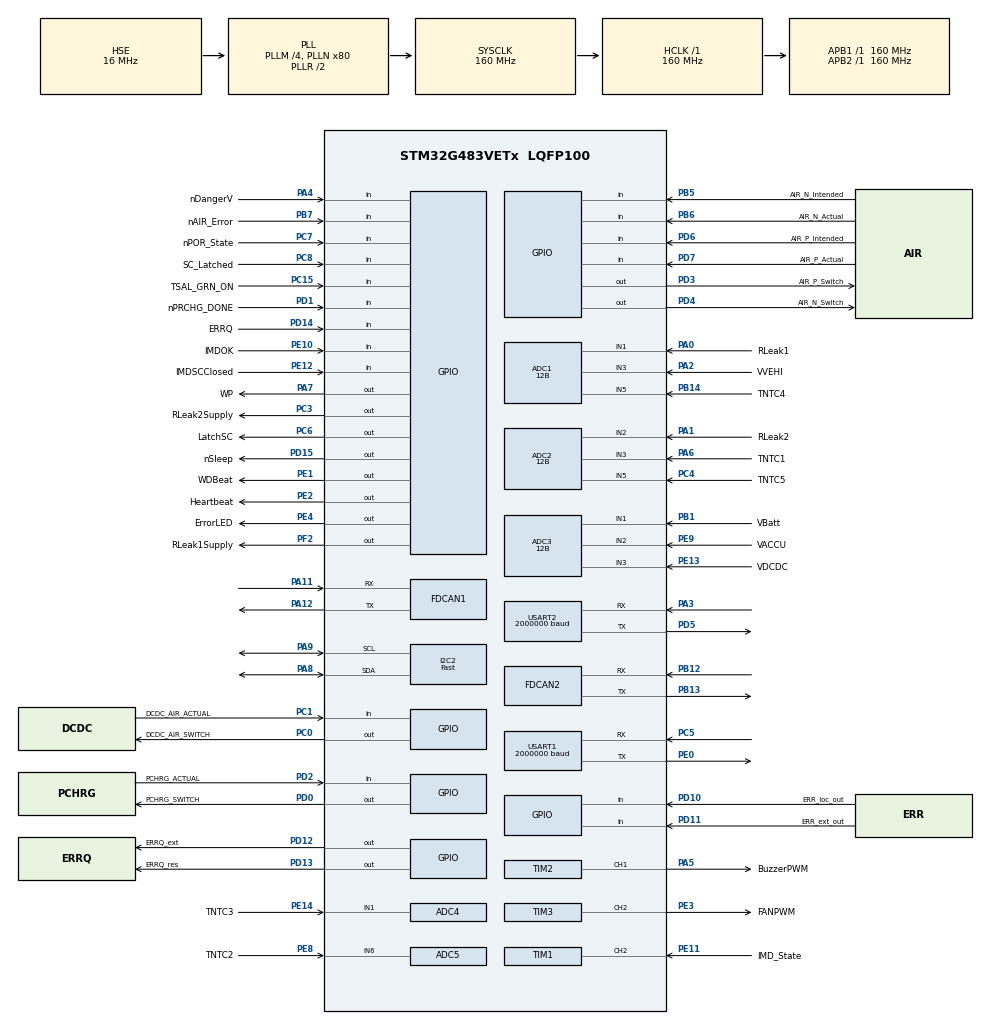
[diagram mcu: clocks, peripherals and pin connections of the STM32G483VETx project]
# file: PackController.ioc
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ADC1.Channel-0\#ChannelRegularConversion=ADC_CHANNEL_1
ADC1.Channel-1\#ChannelRegularConversion=ADC_CHANNEL_3
ADC1.Channel-2\#ChannelRegularConversion=ADC_CHANNEL_5
ADC1.Channel-3\#ChannelRegularConversion=ADC_CHANNEL_VREFINT
ADC1.Channel-IN=ADC_CHANNEL_VREFINT
ADC1.ClockPrescaler=ADC_CLOCK_SYNC_PCLK_DIV4
ADC1.ContinuousConvMode=DISABLE
ADC1.DMAContinuousRequests=ENABLE
ADC1.EOCSelection=ADC_EOC_SEQ_CONV
ADC1.ExternalTrigConv=ADC_EXTERNALTRIG_T6_TRGO
ADC1.ExternalTrigConvEdge=ADC_EXTERNALTRIGCONVEDGE_RISING
ADC1.NbrOfConversion=4
ADC1.NbrOfConversionFlag=1
ADC1.OffsetNumber-0\#ChannelRegularConversion=ADC_OFFSET_NONE
ADC1.OffsetNumber-1\#ChannelRegularConversion=ADC_OFFSET_NONE
ADC1.OffsetNumber-2\#ChannelRegularConversion=ADC_OFFSET_NONE
ADC1.OffsetNumber-3\#ChannelRegularConversion=ADC_OFFSET_NONE
ADC1.Overrun=ADC_OVR_DATA_OVERWRITTEN
ADC1.Rank-0\#ChannelRegularConversion=1
ADC1.Rank-1\#ChannelRegularConversion=2
ADC1.Rank-2\#ChannelRegularConversion=3
ADC1.Rank-3\#ChannelRegularConversion=4
ADC1.Resolution=ADC_RESOLUTION_12B
ADC1.SamplingTime-0\#ChannelRegularConversion=ADC_SAMPLETIME_247CYCLES_5
ADC1.SamplingTime-1\#ChannelRegularConversion=ADC_SAMPLETIME_92CYCLES_5
ADC1.SamplingTime-2\#ChannelRegularConversion=ADC_SAMPLETIME_92CYCLES_5
ADC1.SamplingTime-3\#ChannelRegularConversion=ADC_SAMPLETIME_247CYCLES_5
ADC1.ScanConvMode=ADC_SCAN_ENABLE
ADC1.master=1
ADC2.Channel-0\#ChannelRegularConversion=ADC_CHANNEL_2
ADC2.Channel-1\#ChannelRegularConversion=ADC_CHANNEL_3
ADC2.Channel-2\#ChannelRegularConversion=ADC_CHANNEL_5
ADC2.ClockPrescaler=ADC_CLOCK_SYNC_PCLK_DIV4
ADC2.ContinuousConvMode=DISABLE
ADC2.DMAContinuousRequests=ENABLE
ADC2.EOCSelection=ADC_EOC_SEQ_CONV
ADC2.ExternalTrigConv=ADC_EXTERNALTRIG_T6_TRGO
ADC2.ExternalTrigConvEdge=ADC_EXTERNALTRIGCONVEDGE_RISING
ADC2.NbrOfConversion=3
ADC2.NbrOfConversionFlag=1
ADC2.OffsetNumber-0\#ChannelRegularConversion=ADC_OFFSET_NONE
ADC2.OffsetNumber-1\#ChannelRegularConversion=ADC_OFFSET_NONE
ADC2.OffsetNumber-2\#ChannelRegularConversion=ADC_OFFSET_NONE
ADC2.Overrun=ADC_OVR_DATA_OVERWRITTEN
ADC2.Rank-0\#ChannelRegularConversion=1
ADC2.Rank-1\#ChannelRegularConversion=2
ADC2.Rank-2\#ChannelRegularConversion=3
ADC2.Resolution=ADC_RESOLUTION_12B
ADC2.SamplingTime-0\#ChannelRegularConversion=ADC_SAMPLETIME_247CYCLES_5
ADC2.SamplingTime-1\#ChannelRegularConversion=ADC_SAMPLETIME_92CYCLES_5
ADC2.SamplingTime-2\#ChannelRegularConversion=ADC_SAMPLETIME_92CYCLES_5
ADC2.ScanConvMode=ADC_SCAN_ENABLE
ADC3.Channel-0\#ChannelRegularConversion=ADC_CHANNEL_1
ADC3.Channel-1\#ChannelRegularConversion=ADC_CHANNEL_2
ADC3.Channel-2\#ChannelRegularConversion=ADC_CHANNEL_3
ADC3.ClockPrescaler=ADC_CLOCK_SYNC_PCLK_DIV4
ADC3.ContinuousConvMode=DISABLE
ADC3.DMAContinuousRequests=ENABLE
ADC3.EOCSelection=ADC_EOC_SEQ_CONV
ADC3.ExternalTrigConv=ADC_EXTERNALTRIG_T6_TRGO
ADC3.ExternalTrigConvEdge=ADC_EXTERNALTRIGCONVEDGE_RISING
ADC3.NbrOfConversion=3
ADC3.NbrOfConversionFlag=1
ADC3.OffsetNumber-0\#ChannelRegularConversion=ADC_OFFSET_NONE
ADC3.OffsetNumber-1\#ChannelRegularConversion=ADC_OFFSET_NONE
ADC3.OffsetNumber-2\#ChannelRegularConversion=ADC_OFFSET_NONE
ADC3.Overrun=ADC_OVR_DATA_OVERWRITTEN
ADC3.Rank-0\#ChannelRegularConversion=1
ADC3.Rank-1\#ChannelRegularConversion=2
ADC3.Rank-2\#ChannelRegularConversion=3
ADC3.Resolution=ADC_RESOLUTION_12B
ADC3.SamplingTime-0\#ChannelRegularConversion=ADC_SAMPLETIME_92CYCLES_5
ADC3.SamplingTime-1\#ChannelRegularConversion=ADC_SAMPLETIME_92CYCLES_5
ADC3.SamplingTime-2\#ChannelRegularConversion=ADC_SAMPLETIME_92CYCLES_5
ADC3.ScanConvMode=ADC_SCAN_ENABLE
ADC3.master=1
ADC4.Channel-0\#ChannelRegularConversion=ADC_CHANNEL_1
ADC4.ClockPrescaler=ADC_CLOCK_SYNC_PCLK_DIV4
ADC4.ContinuousConvMode=DISABLE
ADC4.DMAContinuousRequests=ENABLE
ADC4.EOCSelection=ADC_EOC_SEQ_CONV
ADC4.ExternalTrigConv=ADC_EXTERNALTRIG_T6_TRGO
ADC4.ExternalTrigConvEdge=ADC_EXTERNALTRIGCONVEDGE_RISING
ADC4.NbrOfConversionFlag=1
ADC4.OffsetNumber-0\#ChannelRegularConversion=ADC_OFFSET_NONE
ADC4.Overrun=ADC_OVR_DATA_OVERWRITTEN
ADC4.Rank-0\#ChannelRegularConversion=1
ADC4.Resolution=ADC_RESOLUTION_12B
ADC4.SamplingTime-0\#ChannelRegularConversion=ADC_SAMPLETIME_92CYCLES_5
ADC5.Channel-0\#ChannelRegularConversion=ADC_CHANNEL_6
ADC5.ClockPrescaler=ADC_CLOCK_SYNC_PCLK_DIV4
ADC5.ContinuousConvMode=DISABLE
ADC5.DMAContinuousRequests=ENABLE
ADC5.EOCSelection=ADC_EOC_SEQ_CONV
ADC5.ExternalTrigConv=ADC_EXTERNALTRIG_T6_TRGO
ADC5.ExternalTrigConvEdge=ADC_EXTERNALTRIGCONVEDGE_RISING
ADC5.NbrOfConversionFlag=1
ADC5.OffsetNumber-0\#ChannelRegularConversion=ADC_OFFSET_NONE
ADC5.Overrun=ADC_OVR_DATA_OVERWRITTEN
ADC5.Rank-0\#ChannelRegularConversion=1
ADC5.Resolution=ADC_RESOLUTION_12B
ADC5.SamplingTime-0\#ChannelRegularConversion=ADC_SAMPLETIME_92CYCLES_5
Dma.ADC1.0.Direction=DMA_PERIPH_TO_MEMORY
Dma.ADC1.0.EventEnable=DISABLE
Dma.ADC1.0.Instance=DMA1_Channel1
Dma.ADC1.0.MemDataAlignment=DMA_MDATAALIGN_HALFWORD
Dma.ADC1.0.MemInc=DMA_MINC_ENABLE
Dma.ADC1.0.Mode=DMA_CIRCULAR
Dma.ADC1.0.PeriphDataAlignment=DMA_PDATAALIGN_HALFWORD
Dma.ADC1.0.PeriphInc=DMA_PINC_DISABLE
Dma.ADC1.0.Polarity=HAL_DMAMUX_REQ_GEN_RISING
Dma.ADC1.0.Priority=DMA_PRIORITY_VERY_HIGH
Dma.ADC1.0.RequestNumber=1
Dma.ADC1.0.SignalID=NONE
Dma.ADC1.0.SyncEnable=DISABLE
Dma.ADC1.0.SyncPolarity=HAL_DMAMUX_SYNC_NO_EVENT
Dma.ADC1.0.SyncRequestNumber=1
Dma.ADC1.0.SyncSignalID=NONE
Dma.ADC2.1.Direction=DMA_PERIPH_TO_MEMORY
Dma.ADC2.1.EventEnable=DISABLE
Dma.ADC2.1.Instance=DMA1_Channel2
Dma.ADC2.1.MemDataAlignment=DMA_MDATAALIGN_HALFWORD
Dma.ADC2.1.MemInc=DMA_MINC_ENABLE
Dma.ADC2.1.Mode=DMA_CIRCULAR
Dma.ADC2.1.PeriphDataAlignment=DMA_PDATAALIGN_HALFWORD
Dma.ADC2.1.PeriphInc=DMA_PINC_DISABLE
Dma.ADC2.1.Polarity=HAL_DMAMUX_REQ_GEN_RISING
Dma.ADC2.1.Priority=DMA_PRIORITY_VERY_HIGH
Dma.ADC2.1.RequestNumber=1
Dma.ADC2.1.SignalID=NONE
Dma.ADC2.1.SyncEnable=DISABLE
Dma.ADC2.1.SyncPolarity=HAL_DMAMUX_SYNC_NO_EVENT
Dma.ADC2.1.SyncRequestNumber=1
Dma.ADC2.1.SyncSignalID=NONE
Dma.ADC3.2.Direction=DMA_PERIPH_TO_MEMORY
Dma.ADC3.2.EventEnable=DISABLE
Dma.ADC3.2.Instance=DMA1_Channel3
Dma.ADC3.2.MemDataAlignment=DMA_MDATAALIGN_HALFWORD
Dma.ADC3.2.MemInc=DMA_MINC_ENABLE
Dma.ADC3.2.Mode=DMA_CIRCULAR
Dma.ADC3.2.PeriphDataAlignment=DMA_PDATAALIGN_HALFWORD
Dma.ADC3.2.PeriphInc=DMA_PINC_DISABLE
Dma.ADC3.2.Polarity=HAL_DMAMUX_REQ_GEN_RISING
Dma.ADC3.2.Priority=DMA_PRIORITY_VERY_HIGH
Dma.ADC3.2.RequestNumber=1
Dma.ADC3.2.SignalID=NONE
Dma.ADC3.2.SyncEnable=DISABLE
Dma.ADC3.2.SyncPolarity=HAL_DMAMUX_SYNC_NO_EVENT
Dma.ADC3.2.SyncRequestNumber=1
Dma.ADC3.2.SyncSignalID=NONE
Dma.ADC4.3.Direction=DMA_PERIPH_TO_MEMORY
Dma.ADC4.3.EventEnable=DISABLE
Dma.ADC4.3.Instance=DMA1_Channel4
Dma.ADC4.3.MemDataAlignment=DMA_MDATAALIGN_HALFWORD
Dma.ADC4.3.MemInc=DMA_MINC_ENABLE
Dma.ADC4.3.Mode=DMA_CIRCULAR
Dma.ADC4.3.PeriphDataAlignment=DMA_PDATAALIGN_HALFWORD
Dma.ADC4.3.PeriphInc=DMA_PINC_DISABLE
Dma.ADC4.3.Polarity=HAL_DMAMUX_REQ_GEN_RISING
Dma.ADC4.3.Priority=DMA_PRIORITY_HIGH
Dma.ADC4.3.RequestNumber=1
Dma.ADC4.3.SignalID=NONE
Dma.ADC4.3.SyncEnable=DISABLE
Dma.ADC4.3.SyncPolarity=HAL_DMAMUX_SYNC_NO_EVENT
Dma.ADC4.3.SyncRequestNumber=1
Dma.ADC4.3.SyncSignalID=NONE
Dma.ADC5.4.Direction=DMA_PERIPH_TO_MEMORY
Dma.ADC5.4.EventEnable=DISABLE
Dma.ADC5.4.Instance=DMA1_Channel5
Dma.ADC5.4.MemDataAlignment=DMA_MDATAALIGN_HALFWORD
Dma.ADC5.4.MemInc=DMA_MINC_ENABLE
Dma.ADC5.4.Mode=DMA_CIRCULAR
Dma.ADC5.4.PeriphDataAlignment=DMA_PDATAALIGN_HALFWORD
Dma.ADC5.4.PeriphInc=DMA_PINC_DISABLE
Dma.ADC5.4.Polarity=HAL_DMAMUX_REQ_GEN_RISING
Dma.ADC5.4.Priority=DMA_PRIORITY_HIGH
Dma.ADC5.4.RequestNumber=1
Dma.ADC5.4.SignalID=NONE
Dma.ADC5.4.SyncEnable=DISABLE
Dma.ADC5.4.SyncPolarity=HAL_DMAMUX_SYNC_NO_EVENT
Dma.ADC5.4.SyncRequestNumber=1
Dma.ADC5.4.SyncSignalID=NONE
Dma.Request0=ADC1
Dma.Request1=ADC2
Dma.Request2=ADC3
Dma.Request3=ADC4
Dma.Request4=ADC5
Dma.Request5=USART1_RX
Dma.Request6=USART1_TX
Dma.Request7=USART2_RX
Dma.Request8=USART2_TX
Dma.USART1_RX.5.Direction=DMA_PERIPH_TO_MEMORY
Dma.USART1_RX.5.EventEnable=DISABLE
Dma.USART1_RX.5.Instance=DMA2_Channel1
Dma.USART1_RX.5.MemDataAlignment=DMA_MDATAALIGN_BYTE
Dma.USART1_RX.5.MemInc=DMA_MINC_ENABLE
Dma.USART1_RX.5.Mode=DMA_NORMAL
Dma.USART1_RX.5.PeriphDataAlignment=DMA_PDATAALIGN_BYTE
Dma.USART1_RX.5.PeriphInc=DMA_PINC_DISABLE
Dma.USART1_RX.5.Polarity=HAL_DMAMUX_REQ_GEN_RISING
Dma.USART1_RX.5.Priority=DMA_PRIORITY_VERY_HIGH
Dma.USART1_RX.5.RequestNumber=1
Dma.USART1_RX.5.SignalID=NONE
Dma.USART1_RX.5.SyncEnable=DISABLE
Dma.USART1_RX.5.SyncPolarity=HAL_DMAMUX_SYNC_NO_EVENT
Dma.USART1_RX.5.SyncRequestNumber=1
Dma.USART1_RX.5.SyncSignalID=NONE
Dma.USART1_TX.6.Direction=DMA_MEMORY_TO_PERIPH
Dma.USART1_TX.6.EventEnable=DISABLE
Dma.USART1_TX.6.Instance=DMA2_Channel2
Dma.USART1_TX.6.MemDataAlignment=DMA_MDATAALIGN_BYTE
Dma.USART1_TX.6.MemInc=DMA_MINC_ENABLE
Dma.USART1_TX.6.Mode=DMA_NORMAL
Dma.USART1_TX.6.PeriphDataAlignment=DMA_PDATAALIGN_BYTE
Dma.USART1_TX.6.PeriphInc=DMA_PINC_DISABLE
Dma.USART1_TX.6.Polarity=HAL_DMAMUX_REQ_GEN_RISING
Dma.USART1_TX.6.Priority=DMA_PRIORITY_HIGH
Dma.USART1_TX.6.RequestNumber=1
Dma.USART1_TX.6.SignalID=NONE
Dma.USART1_TX.6.SyncEnable=DISABLE
Dma.USART1_TX.6.SyncPolarity=HAL_DMAMUX_SYNC_NO_EVENT
Dma.USART1_TX.6.SyncRequestNumber=1
Dma.USART1_TX.6.SyncSignalID=NONE
Dma.USART2_RX.7.Direction=DMA_PERIPH_TO_MEMORY
Dma.USART2_RX.7.EventEnable=DISABLE
Dma.USART2_RX.7.Instance=DMA2_Channel3
Dma.USART2_RX.7.MemDataAlignment=DMA_MDATAALIGN_BYTE
Dma.USART2_RX.7.MemInc=DMA_MINC_ENABLE
Dma.USART2_RX.7.Mode=DMA_NORMAL
Dma.USART2_RX.7.PeriphDataAlignment=DMA_PDATAALIGN_BYTE
Dma.USART2_RX.7.PeriphInc=DMA_PINC_DISABLE
Dma.USART2_RX.7.Polarity=HAL_DMAMUX_REQ_GEN_RISING
Dma.USART2_RX.7.Priority=DMA_PRIORITY_VERY_HIGH
Dma.USART2_RX.7.RequestNumber=1
Dma.USART2_RX.7.SignalID=NONE
Dma.USART2_RX.7.SyncEnable=DISABLE
Dma.USART2_RX.7.SyncPolarity=HAL_DMAMUX_SYNC_NO_EVENT
Dma.USART2_RX.7.SyncRequestNumber=1
Dma.USART2_RX.7.SyncSignalID=NONE
Dma.USART2_TX.8.Direction=DMA_MEMORY_TO_PERIPH
Dma.USART2_TX.8.EventEnable=DISABLE
Dma.USART2_TX.8.Instance=DMA2_Channel4
Dma.USART2_TX.8.MemDataAlignment=DMA_MDATAALIGN_BYTE
Dma.USART2_TX.8.MemInc=DMA_MINC_ENABLE
Dma.USART2_TX.8.Mode=DMA_NORMAL
Dma.USART2_TX.8.PeriphDataAlignment=DMA_PDATAALIGN_BYTE
Dma.USART2_TX.8.PeriphInc=DMA_PINC_DISABLE
Dma.USART2_TX.8.Polarity=HAL_DMAMUX_REQ_GEN_RISING
Dma.USART2_TX.8.Priority=DMA_PRIORITY_HIGH
Dma.USART2_TX.8.RequestNumber=1
Dma.USART2_TX.8.SignalID=NONE
Dma.USART2_TX.8.SyncEnable=DISABLE
Dma.USART2_TX.8.SyncPolarity=HAL_DMAMUX_SYNC_NO_EVENT
Dma.USART2_TX.8.SyncRequestNumber=1
Dma.USART2_TX.8.SyncSignalID=NONE
FDCAN1.AutoRetransmission=ENABLE
FDCAN1.CalculateBaudRateNominal=1000000
FDCAN1.CalculateTimeQuantumNominal=50.0
FDCAN1.ClockDivider=FDCAN_CLOCK_DIV1
FDCAN1.DataPrescaler=2
FDCAN1.DataSyncJumpWidth=2
FDCAN1.DataTimeSeg1=7
FDCAN1.DataTimeSeg2=2
FDCAN1.ExtFiltersNbr=0
FDCAN1.FrameFormat=FDCAN_FRAME_FD_BRS
FDCAN1.Mode=FDCAN_MODE_NORMAL
FDCAN1.NominalPrescaler=4
FDCAN1.NominalSyncJumpWidth=4
FDCAN1.NominalTimeSeg1=15
FDCAN1.NominalTimeSeg2=4
FDCAN1.ProtocolException=DISABLE
FDCAN1.StdFiltersNbr=1
FDCAN1.TransmitPause=ENABLE
FDCAN1.TxFifoQueueMode=FDCAN_TX_FIFO_OPERATION
FDCAN2.AutoRetransmission=ENABLE
FDCAN2.CalculateBaudRateNominal=1000000
FDCAN2.CalculateTimeQuantumNominal=50.0
FDCAN2.ClockDivider=FDCAN_CLOCK_DIV1
FDCAN2.DataPrescaler=2
FDCAN2.DataSyncJumpWidth=2
FDCAN2.DataTimeSeg1=7
FDCAN2.DataTimeSeg2=2
FDCAN2.ExtFiltersNbr=0
FDCAN2.FrameFormat=FDCAN_FRAME_FD_BRS
FDCAN2.Mode=FDCAN_MODE_NORMAL
FDCAN2.NominalPrescaler=4
FDCAN2.NominalSyncJumpWidth=4
FDCAN2.NominalTimeSeg1=15
FDCAN2.NominalTimeSeg2=4
FDCAN2.ProtocolException=DISABLE
FDCAN2.StdFiltersNbr=1
FDCAN2.TransmitPause=ENABLE
FDCAN2.TxFifoQueueMode=FDCAN_TX_FIFO_OPERATION
I2C2.I2C_Speed_Mode=I2C_Fast
I2C2.Speed=400
Mcu.Family=STM32G4
Mcu.Name=STM32G483VETx
Mcu.Package=LQFP100
NVIC.DMA1_Channel1_IRQn=true\:5\:0\:false\:false\:true\:true\:true\:true
NVIC.DMA1_Channel2_IRQn=true\:5\:0\:false\:false\:true\:true\:true\:true
NVIC.DMA1_Channel3_IRQn=true\:5\:0\:false\:false\:true\:true\:true\:true
NVIC.DMA1_Channel4_IRQn=true\:5\:0\:false\:false\:true\:true\:true\:true
NVIC.DMA1_Channel5_IRQn=true\:5\:0\:false\:false\:true\:true\:true\:true
NVIC.DMA2_Channel1_IRQn=true\:4\:0\:false\:false\:true\:true\:true\:true
NVIC.DMA2_Channel2_IRQn=true\:6\:0\:false\:false\:true\:true\:true\:true
NVIC.DMA2_Channel3_IRQn=true\:4\:0\:false\:false\:true\:true\:true\:true
NVIC.DMA2_Channel4_IRQn=true\:6\:0\:false\:false\:true\:true\:true\:true
NVIC.FDCAN1_IT0_IRQn=true\:3\:0\:false\:false\:true\:true\:true\:true
NVIC.FDCAN1_IT1_IRQn=true\:5\:0\:false\:false\:true\:true\:true\:true
NVIC.FDCAN2_IT0_IRQn=true\:3\:0\:false\:false\:true\:true\:true\:true
NVIC.FDCAN2_IT1_IRQn=true\:5\:0\:false\:false\:true\:true\:true\:true
NVIC.I2C2_ER_IRQn=true\:6\:0\:false\:false\:true\:true\:true\:true
NVIC.I2C2_EV_IRQn=true\:6\:0\:false\:false\:true\:true\:true\:true
NVIC.PriorityGroup=NVIC_PRIORITYGROUP_4
NVIC.TIM1_CC_IRQn=true\:3\:0\:false\:false\:true\:true\:true\:true
NVIC.USART1_IRQn=true\:4\:0\:false\:false\:true\:true\:true\:true
NVIC.USART2_IRQn=true\:4\:0\:false\:false\:true\:true\:true\:true
PA0.GPIO_Label=RLeak1
PA0.Mode=IN1-Single-Ended
PA0.Signal=ADC1_IN1
PA1.GPIO_Label=RLeak2
PA1.Mode=IN2-Single-Ended
PA1.Signal=ADC2_IN2
PA11.Mode=FDCAN_Activate
PA11.Signal=FDCAN1_RX
PA12.Mode=FDCAN_Activate
PA12.Signal=FDCAN1_TX
PA13.Mode=JTAG_5_pins
PA13.Signal=SYS_JTMS-SWDIO
PA14.Mode=JTAG_5_pins
PA14.Signal=SYS_JTCK-SWCLK
PA15.Mode=JTAG_5_pins
PA15.Signal=SYS_JTDI
PA2.GPIO_Label=VVEHI
PA2.Mode=IN3-Single-Ended
PA2.Signal=ADC1_IN3
PA3.Mode=Asynchronous
PA3.Signal=USART2_RX
PA4.GPIO_Label=nDangerV
PA4.Signal=GPIO_Input
PA5.GPIO_Label=BuzzerPWM
PA5.Signal=S_TIM2_CH1
PA6.GPIO_Label=TNTC1
PA6.Mode=IN3-Single-Ended
PA6.Signal=ADC2_IN3
PA7.GPIO_Label=WP
PA7.PinState=GPIO_PIN_SET
PA7.Signal=GPIO_Output
PA8.Mode=I2C
PA8.Signal=I2C2_SDA
PA9.Mode=I2C
PA9.Signal=I2C2_SCL
PB1.GPIO_Label=VBatt
PB1.Mode=IN1-Single-Ended
PB1.Signal=ADC3_IN1
PB12.Mode=FDCAN_Activate
PB12.Signal=FDCAN2_RX
PB13.Mode=FDCAN_Activate
PB13.Signal=FDCAN2_TX
PB14.GPIO_Label=TNTC4
PB14.Mode=IN5-Single-Ended
PB14.Signal=ADC1_IN5
PB3.Mode=JTAG_5_pins
PB3.Signal=SYS_JTDO-SWO
PB4.Mode=JTAG_5_pins
PB4.Signal=SYS_JTRST
PB5.GPIO_Label=AIR_N_Intended
PB5.Signal=GPIO_Input
PB6.GPIO_Label=AIR_N_Actual
PB6.Signal=GPIO_Input
PB7.GPIO_Label=nAIR_Error
PB7.Signal=GPIO_Input
PC0.GPIO_Label=DCDC_AIR_SWITCH
PC0.Signal=GPIO_Output
PC1.GPIO_Label=DCDC_AIR_ACTUAL
PC1.Signal=GPIO_Input
PC15-OSC32_OUT.GPIO_Label=TSAL_GRN_ON
PC15-OSC32_OUT.Signal=GPIO_Input
PC3.GPIO_Label=RLeak2Supply
PC3.Signal=GPIO_Output
PC4.GPIO_Label=TNTC5
PC4.Mode=IN5-Single-Ended
PC4.Signal=ADC2_IN5
PC5.Mode=Asynchronous
PC5.Signal=USART1_RX
PC6.GPIO_Label=LatchSC
PC6.Signal=GPIO_Output
PC7.GPIO_Label=nPOR_State
PC7.Signal=GPIO_Input
PC8.GPIO_Label=SC_Latched
PC8.Signal=GPIO_Input
PD0.GPIO_Label=PCHRG_SWITCH
PD0.Signal=GPIO_Output
PD1.GPIO_Label=nPRCHG_DONE
PD1.Signal=GPIO_Input
PD10.GPIO_Label=ERR_loc_out
PD10.Signal=GPIO_Input
PD11.GPIO_Label=ERR_ext_out
PD11.Signal=GPIO_Input
PD12.GPIO_Label=ERRQ_ext
PD12.PinState=GPIO_PIN_SET
PD12.Signal=GPIO_Output
PD13.GPIO_Label=ERRQ_res
PD13.PinState=GPIO_PIN_SET
PD13.Signal=GPIO_Output
PD14.GPIO_Label=ERRQ
PD14.Signal=GPIO_Input
PD15.GPIO_Label=nSleep
PD15.PinState=GPIO_PIN_SET
PD15.Signal=GPIO_Output
PD2.GPIO_Label=PCHRG_ACTUAL
PD2.Signal=GPIO_Input
PD3.GPIO_Label=AIR_P_Switch
PD3.Signal=GPIO_Output
PD4.GPIO_Label=AIR_N_Switch
PD4.Signal=GPIO_Output
PD5.Mode=Asynchronous
PD5.Signal=USART2_TX
PD6.GPIO_Label=AIR_P_Intended
PD6.Signal=GPIO_Input
PD7.GPIO_Label=AIR_P_Actual
PD7.Signal=GPIO_Input
PE0.Mode=Asynchronous
PE0.Signal=USART1_TX
PE1.GPIO_Label=WDBeat
PE1.Signal=GPIO_Output
PE10.GPIO_Label=IMDOK
PE10.Signal=GPIO_Input
PE11.GPIO_Label=IMD_State
PE11.Signal=S_TIM1_CH2
PE12.GPIO_Label=IMDSCClosed
PE12.Signal=GPIO_Input
PE13.GPIO_Label=VDCDC
PE13.Mode=IN3-Single-Ended
PE13.Signal=ADC3_IN3
PE14.GPIO_Label=TNTC3
PE14.Mode=IN1-Single-Ended
PE14.Signal=ADC4_IN1
PE2.GPIO_Label=Heartbeat
PE2.Signal=GPIO_Output
PE3.GPIO_Label=FANPWM
PE3.Signal=S_TIM3_CH2
PE4.GPIO_Label=ErrorLED
PE4.Signal=GPIO_Output
PE8.GPIO_Label=TNTC2
PE8.Mode=IN6-Single-Ended
PE8.Signal=ADC5_IN6
PE9.GPIO_Label=VACCU
PE9.Mode=IN2-Single-Ended
PE9.Signal=ADC3_IN2
PF0-OSC_IN.Mode=HSE-External-Oscillator
PF0-OSC_IN.Signal=RCC_OSC_IN
PF1-OSC_OUT.Mode=HSE-External-Oscillator
PF1-OSC_OUT.Signal=RCC_OSC_OUT
PF2.GPIO_Label=RLeak1Supply
PF2.Signal=GPIO_Output
ProjectManager.HeapSize=0x0
ProjectManager.StackSize=0x400
ProjectManager.TargetToolchain=STM32CubeIDE
RCC.ADC12Freq_Value=160000000
RCC.ADC345Freq_Value=160000000
RCC.AHBFreq_Value=160000000
RCC.APB1Freq_Value=160000000
RCC.APB1TimFreq_Value=160000000
RCC.APB2Freq_Value=160000000
RCC.APB2TimFreq_Value=160000000
RCC.CortexFreq_Value=160000000
RCC.EXTERNAL_CLOCK_VALUE=12288000
RCC.EnbaleCSS=true
RCC.FDCANCLockSelection=RCC_FDCANCLKSOURCE_PLL
RCC.HCLKFreq_Value=160000000
RCC.HSE_VALUE=16000000
RCC.HSI48_VALUE=48000000
RCC.HSI_VALUE=16000000
RCC.LSE_VALUE=32768
RCC.PLLM=RCC_PLLM_DIV4
RCC.PLLN=80
RCC.PLLP=RCC_PLLP_DIV2
RCC.PLLQ=RCC_PLLQ_DIV4
RCC.PLLR=RCC_PLLR_DIV2
RCC.PLLSourceVirtual=RCC_PLLSOURCE_HSE
RCC.SYSCLKFreq_VALUE=160000000
RCC.SYSCLKSource=RCC_SYSCLKSOURCE_PLLCLK
RCC.USBFreq_Value=80000000
RCC.VCOOutputFreq_Value=320000000
SH.S_TIM1_CH2.0=TIM1_CH2,TriggerSource_TI2FP2
SH.S_TIM1_CH2.1=TIM1_CH2,Input_Capture2_from_TI2
SH.S_TIM1_CH2.2=TIM1_CH2,Input_Capture1_from_TI2
SH.S_TIM2_CH1.0=TIM2_CH1,PWM Generation1 CH1
SH.S_TIM3_CH2.0=TIM3_CH2,PWM Generation2 CH2
TIM1.AutoReloadPreload=TIM_AUTORELOAD_PRELOAD_DISABLE
TIM1.Channel-Input_Capture1_from_TI2=TIM_CHANNEL_1
TIM1.Channel-Input_Capture2_from_TI2=TIM_CHANNEL_2
TIM1.ClockDivision=TIM_CLOCKDIVISION_DIV1
TIM1.CounterMode=TIM_COUNTERMODE_UP
TIM1.ICFilter_CH2=0
TIM1.ICPolarity_CH1=TIM_INPUTCHANNELPOLARITY_FALLING
TIM1.ICPolarity_CH2=TIM_INPUTCHANNELPOLARITY_RISING
TIM1.ICPrescaler-Input_Capture1_from_TI2=TIM_ICPSC_DIV1
TIM1.ICPrescaler-Input_Capture2_from_TI2=TIM_ICPSC_DIV1
TIM1.ICSelection-Input_Capture1_from_TI2=TIM_ICSELECTION_INDIRECTTI
TIM1.ICSelection-Input_Capture2_from_TI2=TIM_ICSELECTION_DIRECTTI
TIM1.Period=65535
TIM1.Prescaler=1599
TIM1.TIM_MasterOutputTrigger=TIM_TRGO_RESET
TIM1.TIM_MasterSlaveMode=TIM_MASTERSLAVEMODE_DISABLE
TIM1.TIM_SlaveMode=TIM_SLAVEMODE_RESET
TIM2.AutoReloadPreload=TIM_AUTORELOAD_PRELOAD_DISABLE
TIM2.Channel-PWM\ Generation1\ CH1=TIM_CHANNEL_1
TIM2.ClockDivision=TIM_CLOCKDIVISION_DIV1
TIM2.CounterMode=TIM_COUNTERMODE_UP
TIM2.Period=249
TIM2.Prescaler=159
TIM2.PulseNoDither_1=125
TIM2.TIM_MasterOutputTrigger=TIM_TRGO_RESET
TIM2.TIM_MasterSlaveMode=TIM_MASTERSLAVEMODE_DISABLE
TIM3.AutoReloadPreload=TIM_AUTORELOAD_PRELOAD_DISABLE
TIM3.Channel-PWM\ Generation2\ CH2=TIM_CHANNEL_2
TIM3.ClockDivision=TIM_CLOCKDIVISION_DIV1
TIM3.CounterMode=TIM_COUNTERMODE_UP
TIM3.Period=19999
TIM3.Prescaler=159
TIM3.PulseNoDither_2=2000
TIM3.TIM_MasterOutputTrigger=TIM_TRGO_RESET
TIM3.TIM_MasterSlaveMode=TIM_MASTERSLAVEMODE_DISABLE
TIM5.AutoReloadPreload=TIM_AUTORELOAD_PRELOAD_DISABLE
TIM5.ClockDivision=TIM_CLOCKDIVISION_DIV1
TIM5.CounterMode=TIM_COUNTERMODE_UP
TIM5.Period=4294967295
TIM5.Prescaler=159
TIM5.TIM_MasterOutputTrigger=TIM_TRGO_RESET
TIM5.TIM_MasterSlaveMode=TIM_MASTERSLAVEMODE_DISABLE
TIM6.AutoReloadPreload=TIM_AUTORELOAD_PRELOAD_DISABLE
TIM6.CounterMode=TIM_COUNTERMODE_UP
TIM6.Period=999
TIM6.Prescaler=159
TIM6.TIM_MasterOutputTrigger=TIM_TRGO_UPDATE
USART1.BaudRate=2000000
USART1.Mode=MODE_TX_RX
USART1.Parity=PARITY_NONE
USART1.StopBits=STOPBITS_1
USART1.VirtualMode-Asynchronous=VM_ASYNC
USART1.WordLength=WORDLENGTH_8B
USART2.BaudRate=2000000
USART2.Mode=MODE_TX_RX
USART2.Parity=PARITY_NONE
USART2.StopBits=STOPBITS_1
USART2.VirtualMode-Asynchronous=VM_ASYNC
USART2.WordLength=WORDLENGTH_8B
VP_ADC1_Vref_Input.Mode=IN-Vrefint
VP_SYS_VS_DBSignals.Mode=DisableDeadBatterySignals
VP_TIM1_VS_ControllerModeReset.Mode=Reset Mode
VP_TIM2_VS_ClockSourceINT.Mode=Internal
VP_TIM3_VS_ClockSourceINT.Mode=Internal
VP_TIM5_VS_ClockSourceINT.Mode=Internal
VP_TIM6_VS_ClockSourceINT.Mode=Enable_Timer
board=custom

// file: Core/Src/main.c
/* USER CODE BEGIN Header */
/**
  ******************************************************************************
  * @file           : main.c
  * @brief          : Main program body
  ******************************************************************************
  * @attention
  *
  * Copyright (c) 2026 STMicroelectronics.
  * All rights reserved.
  *
  * This software is licensed under terms that can be found in the LICENSE file
  * in the root directory of this software component.
  * If no LICENSE file comes with this software, it is provided AS-IS.
  *
  ******************************************************************************
  */
/* USER CODE END Header */
#include "main.h"

/* USER CODE BEGIN Includes */

#include "packcontroller/app/runtime.h"
#include "packcontroller/platform/adc.h"
#include "packcontroller/platform/eeprom.h"
#include "packcontroller/platform/fdcan.h"
#include "packcontroller/platform/runtime.h"
#include "packcontroller/startup/hardfault_record.h"

/* USER CODE END Includes */

ADC_HandleTypeDef hadc1;
ADC_HandleTypeDef hadc2;
ADC_HandleTypeDef hadc3;
ADC_HandleTypeDef hadc4;
ADC_HandleTypeDef hadc5;
DMA_HandleTypeDef hdma_adc1;
DMA_HandleTypeDef hdma_adc2;
DMA_HandleTypeDef hdma_adc3;
DMA_HandleTypeDef hdma_adc4;
DMA_HandleTypeDef hdma_adc5;

FDCAN_HandleTypeDef hfdcan1;
FDCAN_HandleTypeDef hfdcan2;

I2C_HandleTypeDef hi2c2;

TIM_HandleTypeDef htim1;
TIM_HandleTypeDef htim2;
TIM_HandleTypeDef htim3;
TIM_HandleTypeDef htim5;
TIM_HandleTypeDef htim6;

UART_HandleTypeDef huart1;
UART_HandleTypeDef huart2;
DMA_HandleTypeDef hdma_usart1_rx;
DMA_HandleTypeDef hdma_usart1_tx;
DMA_HandleTypeDef hdma_usart2_rx;
DMA_HandleTypeDef hdma_usart2_tx;

void SystemClock_Config(void);
static void MX_GPIO_Init(void);
static void MX_DMA_Init(void);
static void MX_ADC1_Init(void);
static void MX_ADC2_Init(void);
static void MX_ADC3_Init(void);
static void MX_ADC4_Init(void);
static void MX_ADC5_Init(void);
static void MX_FDCAN1_Init(void);
static void MX_FDCAN2_Init(void);
static void MX_I2C2_Init(void);
static void MX_TIM1_Init(void);
static void MX_TIM2_Init(void);
static void MX_TIM3_Init(void);
static void MX_TIM5_Init(void);
static void MX_TIM6_Init(void);
static void MX_USART1_UART_Init(void);
static void MX_USART2_UART_Init(void);

/* USER CODE BEGIN 0 */

extern volatile packcontroller_hardfault_record_t
    g_packcontroller_hardfault_record;

uint32_t packcontroller_platform_time_us(void)
{
  return TIM5->CNT;
}

void packcontroller_platform_toggle_wdbeat(void)
{
  if ((GPIOE->ODR & GPIO_ODR_OD1) == 0U)
  {
    GPIOE->BSRR = GPIO_BSRR_BS1;
  }
  else
  {
    GPIOE->BSRR = GPIO_BSRR_BR1;
  }
}

void packcontroller_platform_toggle_heartbeat(void)
{
  if ((GPIOE->ODR & GPIO_ODR_OD2) == 0U)
  {
    GPIOE->BSRR = GPIO_BSRR_BS2;
  }
  else
  {
    GPIOE->BSRR = GPIO_BSRR_BR2;
  }
}

void packcontroller_platform_set_error_led(bool enabled)
{
  GPIOE->BSRR = enabled ? GPIO_BSRR_BS4 : GPIO_BSRR_BR4;
}

bool packcontroller_platform_stored_hardfault_valid(void)
{
  return packcontroller_hardfault_record_valid(
      &g_packcontroller_hardfault_record);
}

void packcontroller_platform_emergency_shutdown(void)
{
  GPIOD->BSRR = GPIO_BSRR_BR0 | GPIO_BSRR_BR3 | GPIO_BSRR_BR4;
  GPIOC->BSRR = GPIO_BSRR_BR0;
  GPIOE->BSRR = GPIO_BSRR_BR1 | GPIO_BSRR_BS4;
}

/* USER CODE END 0 */

int main(void)
{

  /* MCU Configuration--------------------------------------------------------*/

  /* Reset of all peripherals, Initializes the Flash interface and the Systick. */
  HAL_Init();

  /* Configure the system clock */
  SystemClock_Config();

  /* Initialize all configured peripherals */
  MX_GPIO_Init();
  MX_DMA_Init();
  MX_ADC1_Init();
  MX_ADC2_Init();
  MX_ADC3_Init();
  MX_ADC4_Init();
  MX_ADC5_Init();
  MX_FDCAN1_Init();
  MX_FDCAN2_Init();
  MX_I2C2_Init();
  MX_TIM1_Init();
  MX_TIM2_Init();
  MX_TIM3_Init();
  MX_TIM5_Init();
  MX_TIM6_Init();
  MX_USART1_UART_Init();
  MX_USART2_UART_Init();
  /* USER CODE BEGIN 2 */

  /* TIM5 is the monotonic 1 MHz board timebase. */
  if (HAL_TIM_Base_Start(&htim5) != HAL_OK)
  {
    Error_Handler();
  }

  if (!packcontroller_platform_can_init())
  {
    Error_Handler();
  }

  if (!packcontroller_platform_adc_init())
  {
    Error_Handler();
  }

  if (!packcontroller_platform_eeprom_init())
  {
    Error_Handler();
  }

  packcontroller_runtime_init();

  /* USER CODE END 2 */

  /* Infinite loop */
  while (1)
  {

    /* USER CODE BEGIN 3 */
    packcontroller_runtime_poll();
  }
  /* USER CODE END 3 */
}

void SystemClock_Config(void)
{
  RCC_OscInitTypeDef RCC_OscInitStruct = {0};
  RCC_ClkInitTypeDef RCC_ClkInitStruct = {0};

  /** Configure the main internal regulator output voltage
  */
  HAL_PWREx_ControlVoltageScaling(PWR_REGULATOR_VOLTAGE_SCALE1_BOOST);

  /** Initializes the RCC Oscillators according to the specified parameters
  * in the RCC_OscInitTypeDef structure.
  */
  RCC_OscInitStruct.OscillatorType = RCC_OSCILLATORTYPE_HSE;
  RCC_OscInitStruct.HSEState = RCC_HSE_ON;
  RCC_OscInitStruct.PLL.PLLState = RCC_PLL_ON;
  RCC_OscInitStruct.PLL.PLLSource = RCC_PLLSOURCE_HSE;
  RCC_OscInitStruct.PLL.PLLM = RCC_PLLM_DIV4;
  RCC_OscInitStruct.PLL.PLLN = 80;
  RCC_OscInitStruct.PLL.PLLP = RCC_PLLP_DIV2;
  RCC_OscInitStruct.PLL.PLLQ = RCC_PLLQ_DIV4;
  RCC_OscInitStruct.PLL.PLLR = RCC_PLLR_DIV2;
  if (HAL_RCC_OscConfig(&RCC_OscInitStruct) != HAL_OK)
  {
    Error_Handler();
  }

  /** Initializes the CPU, AHB and APB buses clocks
  */
  RCC_ClkInitStruct.ClockType = RCC_CLOCKTYPE_HCLK|RCC_CLOCKTYPE_SYSCLK
                              |RCC_CLOCKTYPE_PCLK1|RCC_CLOCKTYPE_PCLK2;
  RCC_ClkInitStruct.SYSCLKSource = RCC_SYSCLKSOURCE_PLLCLK;
  RCC_ClkInitStruct.AHBCLKDivider = RCC_SYSCLK_DIV1;
  RCC_ClkInitStruct.APB1CLKDivider = RCC_HCLK_DIV1;
  RCC_ClkInitStruct.APB2CLKDivider = RCC_HCLK_DIV1;

  if (HAL_RCC_ClockConfig(&RCC_ClkInitStruct, FLASH_LATENCY_4) != HAL_OK)
  {
    Error_Handler();
  }

  /** Enables the Clock Security System
  */
  HAL_RCC_EnableCSS();
}

static void MX_ADC1_Init(void)
{

  ADC_MultiModeTypeDef multimode = {0};
  ADC_ChannelConfTypeDef sConfig = {0};

  /** Common config
  */
  hadc1.Instance = ADC1;
  hadc1.Init.ClockPrescaler = ADC_CLOCK_SYNC_PCLK_DIV4;
  hadc1.Init.Resolution = ADC_RESOLUTION_12B;
  hadc1.Init.DataAlign = ADC_DATAALIGN_RIGHT;
  hadc1.Init.GainCompensation = 0;
  hadc1.Init.ScanConvMode = ADC_SCAN_ENABLE;
  hadc1.Init.EOCSelection = ADC_EOC_SEQ_CONV;
  hadc1.Init.LowPowerAutoWait = DISABLE;
  hadc1.Init.ContinuousConvMode = DISABLE;
  hadc1.Init.NbrOfConversion = 4;
  hadc1.Init.DiscontinuousConvMode = DISABLE;
  hadc1.Init.ExternalTrigConv = ADC_EXTERNALTRIG_T6_TRGO;
  hadc1.Init.ExternalTrigConvEdge = ADC_EXTERNALTRIGCONVEDGE_RISING;
  hadc1.Init.DMAContinuousRequests = ENABLE;
  hadc1.Init.Overrun = ADC_OVR_DATA_OVERWRITTEN;
  hadc1.Init.OversamplingMode = DISABLE;
  if (HAL_ADC_Init(&hadc1) != HAL_OK)
  {
    Error_Handler();
  }

  /** Configure the ADC multi-mode
  */
  multimode.Mode = ADC_MODE_INDEPENDENT;
  if (HAL_ADCEx_MultiModeConfigChannel(&hadc1, &multimode) != HAL_OK)
  {
    Error_Handler();
  }

  /** Configure Regular Channel
  */
  sConfig.Channel = ADC_CHANNEL_1;
  sConfig.Rank = ADC_REGULAR_RANK_1;
  sConfig.SamplingTime = ADC_SAMPLETIME_247CYCLES_5;
  sConfig.SingleDiff = ADC_SINGLE_ENDED;
  sConfig.OffsetNumber = ADC_OFFSET_NONE;
  sConfig.Offset = 0;
  if (HAL_ADC_ConfigChannel(&hadc1, &sConfig) != HAL_OK)
  {
    Error_Handler();
  }

  /** Configure Regular Channel
  */
  sConfig.Channel = ADC_CHANNEL_3;
  sConfig.Rank = ADC_REGULAR_RANK_2;
  sConfig.SamplingTime = ADC_SAMPLETIME_92CYCLES_5;
  if (HAL_ADC_ConfigChannel(&hadc1, &sConfig) != HAL_OK)
  {
    Error_Handler();
  }

  /** Configure Regular Channel
  */
  sConfig.Channel = ADC_CHANNEL_5;
  sConfig.Rank = ADC_REGULAR_RANK_3;
  if (HAL_ADC_ConfigChannel(&hadc1, &sConfig) != HAL_OK)
  {
    Error_Handler();
  }

  /** Configure Regular Channel
  */
  sConfig.Channel = ADC_CHANNEL_VREFINT;
  sConfig.Rank = ADC_REGULAR_RANK_4;
  sConfig.SamplingTime = ADC_SAMPLETIME_247CYCLES_5;
  if (HAL_ADC_ConfigChannel(&hadc1, &sConfig) != HAL_OK)
  {
    Error_Handler();
  }

}

static void MX_ADC2_Init(void)
{

  ADC_ChannelConfTypeDef sConfig = {0};

  /** Common config
  */
  hadc2.Instance = ADC2;
  hadc2.Init.ClockPrescaler = ADC_CLOCK_SYNC_PCLK_DIV4;
  hadc2.Init.Resolution = ADC_RESOLUTION_12B;
  hadc2.Init.DataAlign = ADC_DATAALIGN_RIGHT;
  hadc2.Init.GainCompensation = 0;
  hadc2.Init.ScanConvMode = ADC_SCAN_ENABLE;
  hadc2.Init.EOCSelection = ADC_EOC_SEQ_CONV;
  hadc2.Init.LowPowerAutoWait = DISABLE;
  hadc2.Init.ContinuousConvMode = DISABLE;
  hadc2.Init.NbrOfConversion = 3;
  hadc2.Init.DiscontinuousConvMode = DISABLE;
  hadc2.Init.ExternalTrigConv = ADC_EXTERNALTRIG_T6_TRGO;
  hadc2.Init.ExternalTrigConvEdge = ADC_EXTERNALTRIGCONVEDGE_RISING;
  hadc2.Init.DMAContinuousRequests = ENABLE;
  hadc2.Init.Overrun = ADC_OVR_DATA_OVERWRITTEN;
  hadc2.Init.OversamplingMode = DISABLE;
  if (HAL_ADC_Init(&hadc2) != HAL_OK)
  {
    Error_Handler();
  }

  /** Configure Regular Channel
  */
  sConfig.Channel = ADC_CHANNEL_2;
  sConfig.Rank = ADC_REGULAR_RANK_1;
  sConfig.SamplingTime = ADC_SAMPLETIME_247CYCLES_5;
  sConfig.SingleDiff = ADC_SINGLE_ENDED;
  sConfig.OffsetNumber = ADC_OFFSET_NONE;
  sConfig.Offset = 0;
  if (HAL_ADC_ConfigChannel(&hadc2, &sConfig) != HAL_OK)
  {
    Error_Handler();
  }

  /** Configure Regular Channel
  */
  sConfig.Channel = ADC_CHANNEL_3;
  sConfig.Rank = ADC_REGULAR_RANK_2;
  sConfig.SamplingTime = ADC_SAMPLETIME_92CYCLES_5;
  if (HAL_ADC_ConfigChannel(&hadc2, &sConfig) != HAL_OK)
  {
    Error_Handler();
  }

  /** Configure Regular Channel
  */
  sConfig.Channel = ADC_CHANNEL_5;
  sConfig.Rank = ADC_REGULAR_RANK_3;
  if (HAL_ADC_ConfigChannel(&hadc2, &sConfig) != HAL_OK)
  {
    Error_Handler();
  }

}

static void MX_ADC3_Init(void)
{

  ADC_MultiModeTypeDef multimode = {0};
  ADC_ChannelConfTypeDef sConfig = {0};

  /** Common config
  */
  hadc3.Instance = ADC3;
  hadc3.Init.ClockPrescaler = ADC_CLOCK_SYNC_PCLK_DIV4;
  hadc3.Init.Resolution = ADC_RESOLUTION_12B;
  hadc3.Init.DataAlign = ADC_DATAALIGN_RIGHT;
  hadc3.Init.GainCompensation = 0;
  hadc3.Init.ScanConvMode = ADC_SCAN_ENABLE;
  hadc3.Init.EOCSelection = ADC_EOC_SEQ_CONV;
  hadc3.Init.LowPowerAutoWait = DISABLE;
  hadc3.Init.ContinuousConvMode = DISABLE;
  hadc3.Init.NbrOfConversion = 3;
  hadc3.Init.DiscontinuousConvMode = DISABLE;
  hadc3.Init.ExternalTrigConv = ADC_EXTERNALTRIG_T6_TRGO;
  hadc3.Init.ExternalTrigConvEdge = ADC_EXTERNALTRIGCONVEDGE_RISING;
  hadc3.Init.DMAContinuousRequests = ENABLE;
  hadc3.Init.Overrun = ADC_OVR_DATA_OVERWRITTEN;
  hadc3.Init.OversamplingMode = DISABLE;
  if (HAL_ADC_Init(&hadc3) != HAL_OK)
  {
    Error_Handler();
  }

  /** Configure the ADC multi-mode
  */
  multimode.Mode = ADC_MODE_INDEPENDENT;
  if (HAL_ADCEx_MultiModeConfigChannel(&hadc3, &multimode) != HAL_OK)
  {
    Error_Handler();
  }

  /** Configure Regular Channel
  */
  sConfig.Channel = ADC_CHANNEL_1;
  sConfig.Rank = ADC_REGULAR_RANK_1;
  sConfig.SamplingTime = ADC_SAMPLETIME_92CYCLES_5;
  sConfig.SingleDiff = ADC_SINGLE_ENDED;
  sConfig.OffsetNumber = ADC_OFFSET_NONE;
  sConfig.Offset = 0;
  if (HAL_ADC_ConfigChannel(&hadc3, &sConfig) != HAL_OK)
  {
    Error_Handler();
  }

  /** Configure Regular Channel
  */
  sConfig.Channel = ADC_CHANNEL_2;
  sConfig.Rank = ADC_REGULAR_RANK_2;
  if (HAL_ADC_ConfigChannel(&hadc3, &sConfig) != HAL_OK)
  {
    Error_Handler();
  }

  /** Configure Regular Channel
  */
  sConfig.Channel = ADC_CHANNEL_3;
  sConfig.Rank = ADC_REGULAR_RANK_3;
  if (HAL_ADC_ConfigChannel(&hadc3, &sConfig) != HAL_OK)
  {
    Error_Handler();
  }

}

static void MX_ADC4_Init(void)
{

  ADC_ChannelConfTypeDef sConfig = {0};

  /** Common config
  */
  hadc4.Instance = ADC4;
  hadc4.Init.ClockPrescaler = ADC_CLOCK_SYNC_PCLK_DIV4;
  hadc4.Init.Resolution = ADC_RESOLUTION_12B;
  hadc4.Init.DataAlign = ADC_DATAALIGN_RIGHT;
  hadc4.Init.GainCompensation = 0;
  hadc4.Init.ScanConvMode = ADC_SCAN_DISABLE;
  hadc4.Init.EOCSelection = ADC_EOC_SEQ_CONV;
  hadc4.Init.LowPowerAutoWait = DISABLE;
  hadc4.Init.ContinuousConvMode = DISABLE;
  hadc4.Init.NbrOfConversion = 1;
  hadc4.Init.DiscontinuousConvMode = DISABLE;
  hadc4.Init.ExternalTrigConv = ADC_EXTERNALTRIG_T6_TRGO;
  hadc4.Init.ExternalTrigConvEdge = ADC_EXTERNALTRIGCONVEDGE_RISING;
  hadc4.Init.DMAContinuousRequests = ENABLE;
  hadc4.Init.Overrun = ADC_OVR_DATA_OVERWRITTEN;
  hadc4.Init.OversamplingMode = DISABLE;
  if (HAL_ADC_Init(&hadc4) != HAL_OK)
  {
    Error_Handler();
  }

  /** Configure Regular Channel
  */
  sConfig.Channel = ADC_CHANNEL_1;
  sConfig.Rank = ADC_REGULAR_RANK_1;
  sConfig.SamplingTime = ADC_SAMPLETIME_92CYCLES_5;
  sConfig.SingleDiff = ADC_SINGLE_ENDED;
  sConfig.OffsetNumber = ADC_OFFSET_NONE;
  sConfig.Offset = 0;
  if (HAL_ADC_ConfigChannel(&hadc4, &sConfig) != HAL_OK)
  {
    Error_Handler();
  }

}

static void MX_ADC5_Init(void)
{

  ADC_ChannelConfTypeDef sConfig = {0};

  /** Common config
  */
  hadc5.Instance = ADC5;
  hadc5.Init.ClockPrescaler = ADC_CLOCK_SYNC_PCLK_DIV4;
  hadc5.Init.Resolution = ADC_RESOLUTION_12B;
  hadc5.Init.DataAlign = ADC_DATAALIGN_RIGHT;
  hadc5.Init.GainCompensation = 0;
  hadc5.Init.ScanConvMode = ADC_SCAN_DISABLE;
  hadc5.Init.EOCSelection = ADC_EOC_SEQ_CONV;
  hadc5.Init.LowPowerAutoWait = DISABLE;
  hadc5.Init.ContinuousConvMode = DISABLE;
  hadc5.Init.NbrOfConversion = 1;
  hadc5.Init.DiscontinuousConvMode = DISABLE;
  hadc5.Init.ExternalTrigConv = ADC_EXTERNALTRIG_T6_TRGO;
  hadc5.Init.ExternalTrigConvEdge = ADC_EXTERNALTRIGCONVEDGE_RISING;
  hadc5.Init.DMAContinuousRequests = ENABLE;
  hadc5.Init.Overrun = ADC_OVR_DATA_OVERWRITTEN;
  hadc5.Init.OversamplingMode = DISABLE;
  if (HAL_ADC_Init(&hadc5) != HAL_OK)
  {
    Error_Handler();
  }

  /** Configure Regular Channel
  */
  sConfig.Channel = ADC_CHANNEL_6;
  sConfig.Rank = ADC_REGULAR_RANK_1;
  sConfig.SamplingTime = ADC_SAMPLETIME_92CYCLES_5;
  sConfig.SingleDiff = ADC_SINGLE_ENDED;
  sConfig.OffsetNumber = ADC_OFFSET_NONE;
  sConfig.Offset = 0;
  if (HAL_ADC_ConfigChannel(&hadc5, &sConfig) != HAL_OK)
  {
    Error_Handler();
  }

}

static void MX_FDCAN1_Init(void)
{

  hfdcan1.Instance = FDCAN1;
  hfdcan1.Init.ClockDivider = FDCAN_CLOCK_DIV1;
  hfdcan1.Init.FrameFormat = FDCAN_FRAME_FD_BRS;
  hfdcan1.Init.Mode = FDCAN_MODE_NORMAL;
  hfdcan1.Init.AutoRetransmission = ENABLE;
  hfdcan1.Init.TransmitPause = ENABLE;
  hfdcan1.Init.ProtocolException = DISABLE;
  hfdcan1.Init.NominalPrescaler = 4;
  hfdcan1.Init.NominalSyncJumpWidth = 4;
  hfdcan1.Init.NominalTimeSeg1 = 15;
  hfdcan1.Init.NominalTimeSeg2 = 4;
  hfdcan1.Init.DataPrescaler = 2;
  hfdcan1.Init.DataSyncJumpWidth = 2;
  hfdcan1.Init.DataTimeSeg1 = 7;
  hfdcan1.Init.DataTimeSeg2 = 2;
  hfdcan1.Init.StdFiltersNbr = 1;
  hfdcan1.Init.ExtFiltersNbr = 0;
  hfdcan1.Init.TxFifoQueueMode = FDCAN_TX_FIFO_OPERATION;
  if (HAL_FDCAN_Init(&hfdcan1) != HAL_OK)
  {
    Error_Handler();
  }

}

static void MX_FDCAN2_Init(void)
{

  hfdcan2.Instance = FDCAN2;
  hfdcan2.Init.ClockDivider = FDCAN_CLOCK_DIV1;
  hfdcan2.Init.FrameFormat = FDCAN_FRAME_FD_BRS;
  hfdcan2.Init.Mode = FDCAN_MODE_NORMAL;
  hfdcan2.Init.AutoRetransmission = ENABLE;
  hfdcan2.Init.TransmitPause = ENABLE;
  hfdcan2.Init.ProtocolException = DISABLE;
  hfdcan2.Init.NominalPrescaler = 4;
  hfdcan2.Init.NominalSyncJumpWidth = 4;
  hfdcan2.Init.NominalTimeSeg1 = 15;
  hfdcan2.Init.NominalTimeSeg2 = 4;
  hfdcan2.Init.DataPrescaler = 2;
  hfdcan2.Init.DataSyncJumpWidth = 2;
  hfdcan2.Init.DataTimeSeg1 = 7;
  hfdcan2.Init.DataTimeSeg2 = 2;
  hfdcan2.Init.StdFiltersNbr = 1;
  hfdcan2.Init.ExtFiltersNbr = 0;
  hfdcan2.Init.TxFifoQueueMode = FDCAN_TX_FIFO_OPERATION;
  if (HAL_FDCAN_Init(&hfdcan2) != HAL_OK)
  {
    Error_Handler();
  }

}

static void MX_I2C2_Init(void)
{

  hi2c2.Instance = I2C2;
  hi2c2.Init.Timing = 0x00303D5B;
  hi2c2.Init.OwnAddress1 = 0;
  hi2c2.Init.AddressingMode = I2C_ADDRESSINGMODE_7BIT;
  hi2c2.Init.DualAddressMode = I2C_DUALADDRESS_DISABLE;
  hi2c2.Init.OwnAddress2 = 0;
  hi2c2.Init.OwnAddress2Masks = I2C_OA2_NOMASK;
  hi2c2.Init.GeneralCallMode = I2C_GENERALCALL_DISABLE;
  hi2c2.Init.NoStretchMode = I2C_NOSTRETCH_DISABLE;
  if (HAL_I2C_Init(&hi2c2) != HAL_OK)
  {
    Error_Handler();
  }

  /** Configure Analogue filter
  */
  if (HAL_I2CEx_ConfigAnalogFilter(&hi2c2, I2C_ANALOGFILTER_ENABLE) != HAL_OK)
  {
    Error_Handler();
  }

  /** Configure Digital filter
  */
  if (HAL_I2CEx_ConfigDigitalFilter(&hi2c2, 0) != HAL_OK)
  {
    Error_Handler();
  }

}

static void MX_TIM1_Init(void)
{

  TIM_SlaveConfigTypeDef sSlaveConfig = {0};
  TIM_MasterConfigTypeDef sMasterConfig = {0};
  TIM_IC_InitTypeDef sConfigIC = {0};

  htim1.Instance = TIM1;
  htim1.Init.Prescaler = 1599;
  htim1.Init.CounterMode = TIM_COUNTERMODE_UP;
  htim1.Init.Period = 65535;
  htim1.Init.ClockDivision = TIM_CLOCKDIVISION_DIV1;
  htim1.Init.RepetitionCounter = 0;
  htim1.Init.AutoReloadPreload = TIM_AUTORELOAD_PRELOAD_DISABLE;
  if (HAL_TIM_Base_Init(&htim1) != HAL_OK)
  {
    Error_Handler();
  }
  if (HAL_TIM_IC_Init(&htim1) != HAL_OK)
  {
    Error_Handler();
  }
  sSlaveConfig.SlaveMode = TIM_SLAVEMODE_RESET;
  sSlaveConfig.InputTrigger = TIM_TS_TI2FP2;
  sSlaveConfig.TriggerPolarity = TIM_INPUTCHANNELPOLARITY_RISING;
  sSlaveConfig.TriggerFilter = 0;
  if (HAL_TIM_SlaveConfigSynchro(&htim1, &sSlaveConfig) != HAL_OK)
  {
    Error_Handler();
  }
  sMasterConfig.MasterOutputTrigger = TIM_TRGO_RESET;
  sMasterConfig.MasterOutputTrigger2 = TIM_TRGO2_RESET;
  sMasterConfig.MasterSlaveMode = TIM_MASTERSLAVEMODE_DISABLE;
  if (HAL_TIMEx_MasterConfigSynchronization(&htim1, &sMasterConfig) != HAL_OK)
  {
    Error_Handler();
  }
  sConfigIC.ICPolarity = TIM_INPUTCHANNELPOLARITY_FALLING;
  sConfigIC.ICSelection = TIM_ICSELECTION_INDIRECTTI;
  sConfigIC.ICPrescaler = TIM_ICPSC_DIV1;
  sConfigIC.ICFilter = 0;
  if (HAL_TIM_IC_ConfigChannel(&htim1, &sConfigIC, TIM_CHANNEL_1) != HAL_OK)
  {
    Error_Handler();
  }
  sConfigIC.ICPolarity = TIM_INPUTCHANNELPOLARITY_RISING;
  sConfigIC.ICSelection = TIM_ICSELECTION_DIRECTTI;
  if (HAL_TIM_IC_ConfigChannel(&htim1, &sConfigIC, TIM_CHANNEL_2) != HAL_OK)
  {
    Error_Handler();
  }

}

static void MX_TIM2_Init(void)
{

  TIM_ClockConfigTypeDef sClockSourceConfig = {0};
  TIM_MasterConfigTypeDef sMasterConfig = {0};
  TIM_OC_InitTypeDef sConfigOC = {0};

  htim2.Instance = TIM2;
  htim2.Init.Prescaler = 159;
  htim2.Init.CounterMode = TIM_COUNTERMODE_UP;
  htim2.Init.Period = 249;
  htim2.Init.ClockDivision = TIM_CLOCKDIVISION_DIV1;
  htim2.Init.AutoReloadPreload = TIM_AUTORELOAD_PRELOAD_DISABLE;
  if (HAL_TIM_Base_Init(&htim2) != HAL_OK)
  {
    Error_Handler();
  }
  sClockSourceConfig.ClockSource = TIM_CLOCKSOURCE_INTERNAL;
  if (HAL_TIM_ConfigClockSource(&htim2, &sClockSourceConfig) != HAL_OK)
  {
    Error_Handler();
  }
  if (HAL_TIM_PWM_Init(&htim2) != HAL_OK)
  {
    Error_Handler();
  }
  sMasterConfig.MasterOutputTrigger = TIM_TRGO_RESET;
  sMasterConfig.MasterSlaveMode = TIM_MASTERSLAVEMODE_DISABLE;
  if (HAL_TIMEx_MasterConfigSynchronization(&htim2, &sMasterConfig) != HAL_OK)
  {
    Error_Handler();
  }
  sConfigOC.OCMode = TIM_OCMODE_PWM1;
  sConfigOC.Pulse = 125;
  sConfigOC.OCPolarity = TIM_OCPOLARITY_HIGH;
  sConfigOC.OCFastMode = TIM_OCFAST_DISABLE;
  if (HAL_TIM_PWM_ConfigChannel(&htim2, &sConfigOC, TIM_CHANNEL_1) != HAL_OK)
  {
    Error_Handler();
  }
  HAL_TIM_MspPostInit(&htim2);

}

static void MX_TIM3_Init(void)
{

  TIM_ClockConfigTypeDef sClockSourceConfig = {0};
  TIM_MasterConfigTypeDef sMasterConfig = {0};
  TIM_OC_InitTypeDef sConfigOC = {0};

  htim3.Instance = TIM3;
  htim3.Init.Prescaler = 159;
  htim3.Init.CounterMode = TIM_COUNTERMODE_UP;
  htim3.Init.Period = 19999;
  htim3.Init.ClockDivision = TIM_CLOCKDIVISION_DIV1;
  htim3.Init.AutoReloadPreload = TIM_AUTORELOAD_PRELOAD_DISABLE;
  if (HAL_TIM_Base_Init(&htim3) != HAL_OK)
  {
    Error_Handler();
  }
  sClockSourceConfig.ClockSource = TIM_CLOCKSOURCE_INTERNAL;
  if (HAL_TIM_ConfigClockSource(&htim3, &sClockSourceConfig) != HAL_OK)
  {
    Error_Handler();
  }
  if (HAL_TIM_PWM_Init(&htim3) != HAL_OK)
  {
    Error_Handler();
  }
  sMasterConfig.MasterOutputTrigger = TIM_TRGO_RESET;
  sMasterConfig.MasterSlaveMode = TIM_MASTERSLAVEMODE_DISABLE;
  if (HAL_TIMEx_MasterConfigSynchronization(&htim3, &sMasterConfig) != HAL_OK)
  {
    Error_Handler();
  }
  sConfigOC.OCMode = TIM_OCMODE_PWM1;
  sConfigOC.Pulse = 2000;
  sConfigOC.OCPolarity = TIM_OCPOLARITY_HIGH;
  sConfigOC.OCFastMode = TIM_OCFAST_DISABLE;
  if (HAL_TIM_PWM_ConfigChannel(&htim3, &sConfigOC, TIM_CHANNEL_2) != HAL_OK)
  {
    Error_Handler();
  }
  HAL_TIM_MspPostInit(&htim3);

}

static void MX_TIM5_Init(void)
{

  TIM_ClockConfigTypeDef sClockSourceConfig = {0};
  TIM_MasterConfigTypeDef sMasterConfig = {0};

  htim5.Instance = TIM5;
  htim5.Init.Prescaler = 159;
  htim5.Init.CounterMode = TIM_COUNTERMODE_UP;
  htim5.Init.Period = 4294967295;
  htim5.Init.ClockDivision = TIM_CLOCKDIVISION_DIV1;
  htim5.Init.AutoReloadPreload = TIM_AUTORELOAD_PRELOAD_DISABLE;
  if (HAL_TIM_Base_Init(&htim5) != HAL_OK)
  {
    Error_Handler();
  }
  sClockSourceConfig.ClockSource = TIM_CLOCKSOURCE_INTERNAL;
  if (HAL_TIM_ConfigClockSource(&htim5, &sClockSourceConfig) != HAL_OK)
  {
    Error_Handler();
  }
  sMasterConfig.MasterOutputTrigger = TIM_TRGO_RESET;
  sMasterConfig.MasterSlaveMode = TIM_MASTERSLAVEMODE_DISABLE;
  if (HAL_TIMEx_MasterConfigSynchronization(&htim5, &sMasterConfig) != HAL_OK)
  {
    Error_Handler();
  }

}

static void MX_TIM6_Init(void)
{

  TIM_MasterConfigTypeDef sMasterConfig = {0};

  htim6.Instance = TIM6;
  htim6.Init.Prescaler = 159;
  htim6.Init.CounterMode = TIM_COUNTERMODE_UP;
  htim6.Init.Period = 999;
  htim6.Init.AutoReloadPreload = TIM_AUTORELOAD_PRELOAD_DISABLE;
  if (HAL_TIM_Base_Init(&htim6) != HAL_OK)
  {
    Error_Handler();
  }
  sMasterConfig.MasterOutputTrigger = TIM_TRGO_UPDATE;
  sMasterConfig.MasterSlaveMode = TIM_MASTERSLAVEMODE_DISABLE;
  if (HAL_TIMEx_MasterConfigSynchronization(&htim6, &sMasterConfig) != HAL_OK)
  {
    Error_Handler();
  }

}

static void MX_USART1_UART_Init(void)
{

  huart1.Instance = USART1;
  huart1.Init.BaudRate = 2000000;
  huart1.Init.WordLength = UART_WORDLENGTH_8B;
  huart1.Init.StopBits = UART_STOPBITS_1;
  huart1.Init.Parity = UART_PARITY_NONE;
  huart1.Init.Mode = UART_MODE_TX_RX;
  huart1.Init.HwFlowCtl = UART_HWCONTROL_NONE;
  huart1.Init.OverSampling = UART_OVERSAMPLING_16;
  huart1.Init.OneBitSampling = UART_ONE_BIT_SAMPLE_DISABLE;
  huart1.Init.ClockPrescaler = UART_PRESCALER_DIV1;
  huart1.AdvancedInit.AdvFeatureInit = UART_ADVFEATURE_NO_INIT;
  if (HAL_UART_Init(&huart1) != HAL_OK)
  {
    Error_Handler();
  }
  if (HAL_UARTEx_SetTxFifoThreshold(&huart1, UART_TXFIFO_THRESHOLD_1_8) != HAL_OK)
  {
    Error_Handler();
  }
  if (HAL_UARTEx_SetRxFifoThreshold(&huart1, UART_RXFIFO_THRESHOLD_1_8) != HAL_OK)
  {
    Error_Handler();
  }
  if (HAL_UARTEx_DisableFifoMode(&huart1) != HAL_OK)
  {
    Error_Handler();
  }

}

static void MX_USART2_UART_Init(void)
{

  huart2.Instance = USART2;
  huart2.Init.BaudRate = 2000000;
  huart2.Init.WordLength = UART_WORDLENGTH_8B;
  huart2.Init.StopBits = UART_STOPBITS_1;
  huart2.Init.Parity = UART_PARITY_NONE;
  huart2.Init.Mode = UART_MODE_TX_RX;
  huart2.Init.HwFlowCtl = UART_HWCONTROL_NONE;
  huart2.Init.OverSampling = UART_OVERSAMPLING_16;
  huart2.Init.OneBitSampling = UART_ONE_BIT_SAMPLE_DISABLE;
  huart2.Init.ClockPrescaler = UART_PRESCALER_DIV1;
  huart2.AdvancedInit.AdvFeatureInit = UART_ADVFEATURE_NO_INIT;
  if (HAL_UART_Init(&huart2) != HAL_OK)
  {
    Error_Handler();
  }
  if (HAL_UARTEx_SetTxFifoThreshold(&huart2, UART_TXFIFO_THRESHOLD_1_8) != HAL_OK)
  {
    Error_Handler();
  }
  if (HAL_UARTEx_SetRxFifoThreshold(&huart2, UART_RXFIFO_THRESHOLD_1_8) != HAL_OK)
  {
    Error_Handler();
  }
  if (HAL_UARTEx_DisableFifoMode(&huart2) != HAL_OK)
  {
    Error_Handler();
  }

}

static void MX_DMA_Init(void)
{

  /* DMA controller clock enable */
  __HAL_RCC_DMAMUX1_CLK_ENABLE();
  __HAL_RCC_DMA1_CLK_ENABLE();
  __HAL_RCC_DMA2_CLK_ENABLE();

  /* DMA interrupt init */
  /* DMA1_Channel1_IRQn interrupt configuration */
  HAL_NVIC_SetPriority(DMA1_Channel1_IRQn, 5, 0);
  HAL_NVIC_EnableIRQ(DMA1_Channel1_IRQn);
  /* DMA1_Channel2_IRQn interrupt configuration */
  HAL_NVIC_SetPriority(DMA1_Channel2_IRQn, 5, 0);
  HAL_NVIC_EnableIRQ(DMA1_Channel2_IRQn);
  /* DMA1_Channel3_IRQn interrupt configuration */
  HAL_NVIC_SetPriority(DMA1_Channel3_IRQn, 5, 0);
  HAL_NVIC_EnableIRQ(DMA1_Channel3_IRQn);
  /* DMA1_Channel4_IRQn interrupt configuration */
  HAL_NVIC_SetPriority(DMA1_Channel4_IRQn, 5, 0);
  HAL_NVIC_EnableIRQ(DMA1_Channel4_IRQn);
  /* DMA1_Channel5_IRQn interrupt configuration */
  HAL_NVIC_SetPriority(DMA1_Channel5_IRQn, 5, 0);
  HAL_NVIC_EnableIRQ(DMA1_Channel5_IRQn);
  /* DMA2_Channel1_IRQn interrupt configuration */
  HAL_NVIC_SetPriority(DMA2_Channel1_IRQn, 4, 0);
  HAL_NVIC_EnableIRQ(DMA2_Channel1_IRQn);
  /* DMA2_Channel2_IRQn interrupt configuration */
  HAL_NVIC_SetPriority(DMA2_Channel2_IRQn, 6, 0);
  HAL_NVIC_EnableIRQ(DMA2_Channel2_IRQn);
  /* DMA2_Channel3_IRQn interrupt configuration */
  HAL_NVIC_SetPriority(DMA2_Channel3_IRQn, 4, 0);
  HAL_NVIC_EnableIRQ(DMA2_Channel3_IRQn);
  /* DMA2_Channel4_IRQn interrupt configuration */
  HAL_NVIC_SetPriority(DMA2_Channel4_IRQn, 6, 0);
  HAL_NVIC_EnableIRQ(DMA2_Channel4_IRQn);

}

static void MX_GPIO_Init(void)
{
  GPIO_InitTypeDef GPIO_InitStruct = {0};

  /* GPIO Ports Clock Enable */
  __HAL_RCC_GPIOE_CLK_ENABLE();
  __HAL_RCC_GPIOC_CLK_ENABLE();
  __HAL_RCC_GPIOF_CLK_ENABLE();
  __HAL_RCC_GPIOA_CLK_ENABLE();
  __HAL_RCC_GPIOB_CLK_ENABLE();
  __HAL_RCC_GPIOD_CLK_ENABLE();

  /*Configure GPIO pin Output Level */
  HAL_GPIO_WritePin(GPIOE, Heartbeat_Pin|ErrorLED_Pin|WDBeat_Pin, GPIO_PIN_RESET);

  /*Configure GPIO pin Output Level */
  HAL_GPIO_WritePin(GPIOC, DCDC_AIR_SWITCH_Pin|RLeak2Supply_Pin|LatchSC_Pin, GPIO_PIN_RESET);

  /*Configure GPIO pin Output Level */
  HAL_GPIO_WritePin(RLeak1Supply_GPIO_Port, RLeak1Supply_Pin, GPIO_PIN_RESET);

  /*Configure GPIO pin Output Level */
  HAL_GPIO_WritePin(WP_GPIO_Port, WP_Pin, GPIO_PIN_SET);

  /*Configure GPIO pin Output Level */
  HAL_GPIO_WritePin(GPIOD, ERRQ_ext_Pin|ERRQ_res_Pin|nSleep_Pin, GPIO_PIN_SET);

  /*Configure GPIO pin Output Level */
  HAL_GPIO_WritePin(GPIOD, PCHRG_SWITCH_Pin|AIR_P_Switch_Pin|AIR_N_Switch_Pin, GPIO_PIN_RESET);

  /*Configure GPIO pins : Heartbeat_Pin ErrorLED_Pin WDBeat_Pin */
  GPIO_InitStruct.Pin = Heartbeat_Pin|ErrorLED_Pin|WDBeat_Pin;
  GPIO_InitStruct.Mode = GPIO_MODE_OUTPUT_PP;
  GPIO_InitStruct.Pull = GPIO_NOPULL;
  GPIO_InitStruct.Speed = GPIO_SPEED_FREQ_LOW;
  HAL_GPIO_Init(GPIOE, &GPIO_InitStruct);

  /*Configure GPIO pins : TSAL_GRN_ON_Pin DCDC_AIR_ACTUAL_Pin nPOR_State_Pin SC_Latched_Pin */
  GPIO_InitStruct.Pin = TSAL_GRN_ON_Pin|DCDC_AIR_ACTUAL_Pin|nPOR_State_Pin|SC_Latched_Pin;
  GPIO_InitStruct.Mode = GPIO_MODE_INPUT;
  GPIO_InitStruct.Pull = GPIO_NOPULL;
  HAL_GPIO_Init(GPIOC, &GPIO_InitStruct);

  /*Configure GPIO pins : DCDC_AIR_SWITCH_Pin RLeak2Supply_Pin LatchSC_Pin */
  GPIO_InitStruct.Pin = DCDC_AIR_SWITCH_Pin|RLeak2Supply_Pin|LatchSC_Pin;
  GPIO_InitStruct.Mode = GPIO_MODE_OUTPUT_PP;
  GPIO_InitStruct.Pull = GPIO_NOPULL;
  GPIO_InitStruct.Speed = GPIO_SPEED_FREQ_LOW;
  HAL_GPIO_Init(GPIOC, &GPIO_InitStruct);

  /*Configure GPIO pin : RLeak1Supply_Pin */
  GPIO_InitStruct.Pin = RLeak1Supply_Pin;
  GPIO_InitStruct.Mode = GPIO_MODE_OUTPUT_PP;
  GPIO_InitStruct.Pull = GPIO_NOPULL;
  GPIO_InitStruct.Speed = GPIO_SPEED_FREQ_LOW;
  HAL_GPIO_Init(RLeak1Supply_GPIO_Port, &GPIO_InitStruct);

  /*Configure GPIO pin : nDangerV_Pin */
  GPIO_InitStruct.Pin = nDangerV_Pin;
  GPIO_InitStruct.Mode = GPIO_MODE_INPUT;
  GPIO_InitStruct.Pull = GPIO_NOPULL;
  HAL_GPIO_Init(nDangerV_GPIO_Port, &GPIO_InitStruct);

  /*Configure GPIO pin : WP_Pin */
  GPIO_InitStruct.Pin = WP_Pin;
  GPIO_InitStruct.Mode = GPIO_MODE_OUTPUT_PP;
  GPIO_InitStruct.Pull = GPIO_NOPULL;
  GPIO_InitStruct.Speed = GPIO_SPEED_FREQ_LOW;
  HAL_GPIO_Init(WP_GPIO_Port, &GPIO_InitStruct);

  /*Configure GPIO pins : IMDOK_Pin IMDSCClosed_Pin */
  GPIO_InitStruct.Pin = IMDOK_Pin|IMDSCClosed_Pin;
  GPIO_InitStruct.Mode = GPIO_MODE_INPUT;
  GPIO_InitStruct.Pull = GPIO_NOPULL;
  HAL_GPIO_Init(GPIOE, &GPIO_InitStruct);

  /*Configure GPIO pins : ERR_loc_out_Pin ERR_ext_out_Pin ERRQ_Pin nPRCHG_DONE_Pin
                           PCHRG_ACTUAL_Pin AIR_P_Intended_Pin AIR_P_Actual_Pin */
  GPIO_InitStruct.Pin = ERR_loc_out_Pin|ERR_ext_out_Pin|ERRQ_Pin|nPRCHG_DONE_Pin
                          |PCHRG_ACTUAL_Pin|AIR_P_Intended_Pin|AIR_P_Actual_Pin;
  GPIO_InitStruct.Mode = GPIO_MODE_INPUT;
  GPIO_InitStruct.Pull = GPIO_NOPULL;
  HAL_GPIO_Init(GPIOD, &GPIO_InitStruct);

  /*Configure GPIO pins : ERRQ_ext_Pin ERRQ_res_Pin nSleep_Pin PCHRG_SWITCH_Pin
                           AIR_P_Switch_Pin AIR_N_Switch_Pin */
  GPIO_InitStruct.Pin = ERRQ_ext_Pin|ERRQ_res_Pin|nSleep_Pin|PCHRG_SWITCH_Pin
                          |AIR_P_Switch_Pin|AIR_N_Switch_Pin;
  GPIO_InitStruct.Mode = GPIO_MODE_OUTPUT_PP;
  GPIO_InitStruct.Pull = GPIO_NOPULL;
  GPIO_InitStruct.Speed = GPIO_SPEED_FREQ_LOW;
  HAL_GPIO_Init(GPIOD, &GPIO_InitStruct);

  /*Configure GPIO pins : AIR_N_Intended_Pin AIR_N_Actual_Pin nAIR_Error_Pin */
  GPIO_InitStruct.Pin = AIR_N_Intended_Pin|AIR_N_Actual_Pin|nAIR_Error_Pin;
  GPIO_InitStruct.Mode = GPIO_MODE_INPUT;
  GPIO_InitStruct.Pull = GPIO_NOPULL;
  HAL_GPIO_Init(GPIOB, &GPIO_InitStruct);

/* USER CODE BEGIN MX_GPIO_Init_2 */
  /* Set timer-driven outputs LOW via BSRR before their AF mode is enabled. */
  HAL_GPIO_WritePin(BuzzerPWM_GPIO_Port, BuzzerPWM_Pin, GPIO_PIN_RESET);
  HAL_GPIO_WritePin(FANPWM_GPIO_Port, FANPWM_Pin, GPIO_PIN_RESET);
/* USER CODE END MX_GPIO_Init_2 */
}

void Error_Handler(void)
{
  __disable_irq();
  while (1)
  {
  }
}
